# ATmega32C1 device description
Architecture: AVR8; Family: megaAVR
Registers are 8-bit, access not given, no defined reset value unless marked. A register's access mark holds for its fields unless they carry their own. Offsets are from the block's base; [hi:lo] are bit positions; {n}, {i} and the like mark numbered series; 'fields as' and 'values as' point back to an identical list.

## LOCKBIT — Lockbits
Instances: LOCKBIT 0 in lockbits
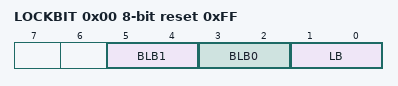
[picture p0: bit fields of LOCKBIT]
0x00 LOCKBIT reset 0xFF
  [5:4] BLB1 — Boot Loader Protection Mode
    0=LPM_SPM_DISABLE (LPM and SPM prohibited in Boot Section); 1=LPM_DISABLE (LPM prohibited in Boot Section); 2=SPM_DISABLE (SPM prohibited in Boot Section); 3=NO_LOCK (No lock on SPM and LPM in Boot Section)
  [3:2] BLB0 — Boot Loader Protection Mode
    0=LPM_SPM_DISABLE (LPM and SPM prohibited in Application Section); 1=LPM_DISABLE (LPM prohibited in Application Section); 2=SPM_DISABLE (SPM prohibited in Application Section); 3=NO_LOCK (No lock on SPM and LPM in Application Section)
  [1:0] LB — Memory Lock
    0=PROG_VER_DISABLED (Further programming and verification disabled); 2=PROG_DISABLED (Further programming disabled); 3=NO_LOCK (No memory lock features enabled)

## PORTB — I/O Port
Instances: PORTB 0x00
0x23 PINB — Port B Input Pins
0x24 DDRB — Port B Data Direction Register
0x25 PORTB — Port B Data Register

## PORTC — I/O Port
Instances: PORTC 0x00
0x26 PINC — Port C Input Pins
0x27 DDRC — Port C Data Direction Register
0x28 PORTC — Port C Data Register

## PORTD — I/O Port
Instances: PORTD 0x00
0x29 PIND — Port D Input Pins
0x2A DDRD — Port D Data Direction Register
0x2B PORTD — Port D Data Register

## PORTE — I/O Port
Instances: PORTE 0x00
0x2C PINE bits used 2:0 — Port E Input Pins
0x2D DDRE bits used 2:0 — Port E Data Direction Register
0x2E PORTE bits used 2:0 — Port E Data Register

## AC — Analog Comparator
Instances: AC 0x00
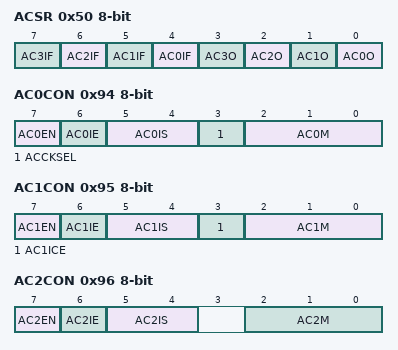
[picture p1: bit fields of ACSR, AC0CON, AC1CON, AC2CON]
0x50 ACSR — Analog Comparator Status Register
  [n+4] AC{n}IF (n=0..3) — Analog Comparator {n} Interrupt Flag Bit
  [n] AC{n}O (n=0..3) — Analog Comparator {n} Output Bit
0x94 AC0CON — Analog Comparator 0 Control Register
  [7] AC0EN — Analog Comparator 0 Enable Bit
  [6] AC0IE — Analog Comparator 0 Interrupt Enable Bit
  [5:4] AC0IS — Analog Comparator 0 Interrupt Select Bits
  [3] ACCKSEL — Analog Comparator Clock Select
  [2:0] AC0M — Analog Comparator 0 Multiplexer Register
0x95 AC1CON — Analog Comparator 1 Control Register
  [7] AC1EN — Analog Comparator 1 Enable Bit
  [6] AC1IE — Analog Comparator 1 Interrupt Enable Bit
  [5:4] AC1IS — Analog Comparator 1 Interrupt Select Bit
    0=Interrupt on Toggle; 2=Interrupt on Falling Edge; 3=Interrupt on Rising Edge
  [3] AC1ICE — Analog Comparator 1 Interrupt Capture Enable Bit
  [2:0] AC1M — Analog Comparator 1 Multiplexer Register
0x96 AC2CON — Analog Comparator 2 Control Register
  [7] AC2EN — Analog Comparator 2 Enable Bit
  [6] AC2IE — Analog Comparator 2 Interrupt Enable Bit
  [5:4] AC2IS — Analog Comparator 2 Interrupt Select Bit
    values as AC1CON.AC1IS
  [2:0] AC2M — Analog Comparator 2 Multiplexer Register
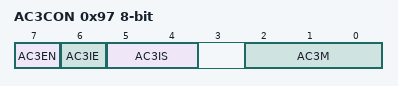
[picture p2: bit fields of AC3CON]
0x97 AC3CON — Analog Comparator 3 Control Register
  [7] AC3EN — Analog Comparator 3 Enable Bit
  [6] AC3IE — Analog Comparator 3 Interrupt Enable Bit
  [5:4] AC3IS — Analog Comparator 3 Interrupt Select Bit
    values as AC1CON.AC1IS
  [2:0] AC3M — Analog Comparator 3 Multiplexer Register

## DAC — Digital-to-Analog Converter
Instances: DAC 0x00
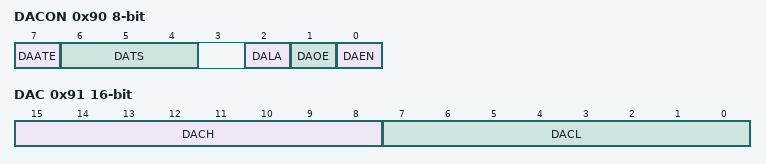
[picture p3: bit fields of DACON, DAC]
0x90 DACON — DAC Control Register
  [7] DAATE — DAC Auto Trigger Enable Bit
  [6:4] DATS — DAC Trigger Selection Bits
    0=Analog Comparator 0; 1=Analog Comparator 1; 2=External Interrupt Request 0; 3=Timer/Counter0 Compare Match A; 4=Timer/Counter0 Overflow; 5=Timer/Counter1 Compare Match B; 6=Timer/Counter1 Overflow; 7=Timer/Counter1 Capture Event
  [2] DALA — DAC Left Adjust
  [1] DAOE — DAC Output Enable
  [0] DAEN — DAC Enable Bit
0x91 DAC 16-bit — DAC Data Register
  [15:8] DACH — DAC Data Register High Byte Bits
  [7:0] DACL — DAC Data Register Low Byte Bits
